AUTOSAR XML (schema 4-2-2)
standard types defined: uint16, uint8
package /AUTOSAR/Compositions
  composition sw component type TopComposition
    component BottomComposition: type=BottomComposition
  composition sw component type BottomComposition
    component CptObsPrototype: type=CptObs
    component CptCtrlPrototype: type=CptCtrl
    connect CptCtrlPrototype.PpAllDataTypeImplicit -> CptObsPrototype.RpAllDataTypeImplicit
    connect CptCtrlPrototype.PpAllDataTypeExplicit -> CptObsPrototype.RpAllDataTypeExplicit
package /AUTOSAR/SwcImplementations
  swc implementation swcImplementation_CptObs: behavior=IbObs
  swc implementation swcImplementation_CptCtrl: behavior=IbCtrl
package /AUTOSAR/System
  system system_0
    system mapping SystemMapping_0
      sw-impl-mappings:
        swc to impl mapping CptReceiverPrototypeImplMapping: component-implementation=swcImplementation_CptObs, component=rootSwCompositionPrototype_0.BottomComposition.CptObsPrototype.CptObsPrototype
        swc to impl mapping CptSenderPrototypeImplMapping: component-implementation=swcImplementation_CptCtrl, component=rootSwCompositionPrototype_0.BottomComposition.CptCtrlPrototype.CptCtrlPrototype
      sw-mappings:
        swc to ecu mapping ECUA_SwcToEcuMapping: component=rootSwCompositionPrototype_0.BottomComposition.BottomComposition, ecu-instance=ECUA
    root-software-compositions:
      root sw composition prototype rootSwCompositionPrototype_0: software-composition=TopComposition
package /AUTOSAR/Components
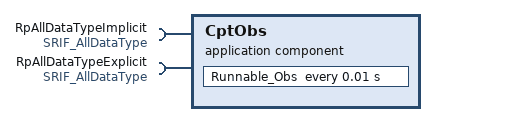
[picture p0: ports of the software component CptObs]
  application sw component type CptObs
    require port RpAllDataTypeImplicit: required-interface=SRIF_AllDataType
      required-com-specs:
        data-element=dataElementPrimitive, handle-never-received=true, init-value=0
        data-element=dataElementStruct, handle-never-received=true, init-value=fields=[0, 1, 2]
        data-element=dataElementArray, handle-never-received=true, init-value=[0]
    require port RpAllDataTypeExplicit: required-interface=SRIF_AllDataType
      required-com-specs:
        data-element=dataElementPrimitive, handle-never-received=true, init-value=0
        data-element=dataElementStruct, handle-never-received=true, init-value=fields=[0, 1, 2]
        data-element=dataElementArray, handle-never-received=true, init-value=[0]
    behavior IbObs
      timing event timingEvent_10: start-on-event=Runnable_Obs, period=0.01
      runnable Runnable_Obs: symbol=AppRunnable_Obs
        data-read-access:
          access dataReadAccess_Primitive: accessed-variable=RpAllDataTypeImplicit.dataElementPrimitive
          access dataReadAccess_Array: accessed-variable=RpAllDataTypeImplicit.dataElementArray
          access dataReadAccess_Struct: accessed-variable=RpAllDataTypeImplicit.dataElementStruct
        data-receive-point-by-arguments:
          access DataReceiveByArgPrimitive: accessed-variable=RpAllDataTypeExplicit.dataElementPrimitive
          access DataReceiveByArgArray: accessed-variable=RpAllDataTypeExplicit.dataElementArray
          access DataReceiveByArgStruct: accessed-variable=RpAllDataTypeExplicit.dataElementStruct
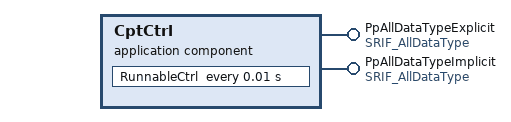
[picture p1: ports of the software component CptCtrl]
  application sw component type CptCtrl
    provide port PpAllDataTypeExplicit: provided-interface=SRIF_AllDataType
    provide port PpAllDataTypeImplicit: provided-interface=SRIF_AllDataType
    behavior IbCtrl
      timing event timingEvent_10: start-on-event=RunnableCtrl, period=0.01
      runnable RunnableCtrl: symbol=AppRunnableCtrl
        data-send-points:
          access DataSendPointsPrimitive: accessed-variable=PpAllDataTypeExplicit.dataElementPrimitive
          access dataSendPointsArray: accessed-variable=PpAllDataTypeExplicit.dataElementArray
          access dataSendPointsStruct: accessed-variable=PpAllDataTypeExplicit.dataElementStruct
        data-write-access:
          access dataWriteAccess_Primitive: accessed-variable=PpAllDataTypeImplicit.dataElementPrimitive
          access dataWriteAccess_Array: accessed-variable=PpAllDataTypeImplicit.dataElementArray
          access dataWriteAccess_Struct: accessed-variable=PpAllDataTypeImplicit.dataElementStruct
package /AUTOSAR/Interfaces
  sender receiver interface SRIF_AllDataType
    data dataElementPrimitive: type=PrimitiveUint16
    data dataElementArray: type=ArrayUint8
    data dataElementStruct: type=StructA
package /AUTOSAR/DataTypes
  impl type PrimitiveUint16: category=VALUE, base-type=uint16
  impl type ArrayUint8: category=ARRAY
    element subElement: category=VALUE, array-size=10, base-type=uint8
  impl type StructA: category=STRUCTURE
    element Crc_Uint8: category=VALUE, base-type=uint8
    element Data_Uint16: category=VALUE, base-type=uint16
    element Counter_Uint8: category=VALUE, base-type=uint8
package /SystemInfo/EcuInstances
  ecu instance ECUA: com-configuration-gw-time-base=0.005, com-configuration-rx-time-base=0.005, com-configuration-tx-time-base=0.005, sleep-mode-supported=false, wake-up-over-bus-supported=false
